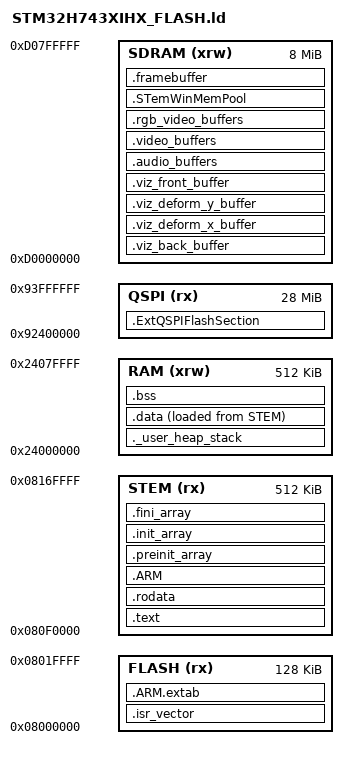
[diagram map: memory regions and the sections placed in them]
/*
******************************************************************************
**
** @file        : LinkerScript.ld
**
** @author      : Auto-generated by STM32CubeIDE
**
**  Abstract    : Linker script for STM32H743I-EVAL Board embedding STM32H743XIHx Device from stm32h7 series
**                      28672Kbytes QSPI
**                      512Kbytes ROM
**                      512Kbytes RAM
**                      32768Kbytes SDRAM
**
**                Set heap size, stack size and stack location according
**                to application requirements.
**
**                Set memory bank area and size if external memory is used
**
**  Target      : STMicroelectronics STM32
**
**  Distribution: The file is distributed as is, without any warranty
**                of any kind.
**
******************************************************************************
** @attention
**
** Copyright (c) 2022 STMicroelectronics.
** All rights reserved.
**
** This software is licensed under terms that can be found in the LICENSE file
** in the root directory of this software component.
** If no LICENSE file comes with this software, it is provided AS-IS.
**
******************************************************************************
*/

/* Entry Point */
ENTRY(Reset_Handler)

/* Highest address of the user mode stack */
_estack = 0x24080000;    /* end of RAM */
/* Generate a link error if heap   and stack don't fit into RAM */
_Min_Heap_Size = 0x7000;      /* required amount of heap  */
_Min_Stack_Size = 0x3000; /* required amount of stack */

/* Specify the memory areas */
MEMORY
{
FLASH (rx)      : ORIGIN = 0x08000000, LENGTH = 128K
RAM (xrw)      : ORIGIN = 0x24000000, LENGTH = 512K
STEM (rx)      : ORIGIN = 0x080F0000, LENGTH = 512K 
SDRAM    (xrw)    : ORIGIN = 0xD0000000,   LENGTH = 8192K
QSPI    (rx)    : ORIGIN = 0x92400000,   LENGTH = 28672K
}

/* Define output sections */
SECTIONS
{
  /* The startup code goes first into FLASH */
  .isr_vector :
  {
    . = ALIGN(4);
    KEEP(*(.isr_vector)) /* Startup code */
    . = ALIGN(4);
  } >FLASH

  /* The program code and other data goes into FLASH */
  .text :
  {
    . = ALIGN(4);
    *(.text)           /* .text sections (code) */
    *(.text*)          /* .text* sections (code) */
    *(.glue_7)         /* glue arm to thumb code */
    *(.glue_7t)        /* glue thumb to arm code */
    *(.eh_frame)

    KEEP (*(.init))
    KEEP (*(.fini))

    . = ALIGN(4);
    _etext = .;        /* define a global symbols at end of code */
  } >STEM

  /* Constant data goes into FLASH */
  .rodata :
  {
    . = ALIGN(4);
    *(.rodata)         /* .rodata sections (constants, strings, etc.) */
    *(.rodata*)        /* .rodata* sections (constants, strings, etc.) */
    . = ALIGN(4);
  } >STEM

  .ARM.extab   : { *(.ARM.extab* .gnu.linkonce.armextab.*) } >FLASH
  .ARM : {
    __exidx_start = .;
    *(.ARM.exidx*)
    __exidx_end = .;
  } >STEM

  .preinit_array     :
  {
    PROVIDE_HIDDEN (__preinit_array_start = .);
    KEEP (*(.preinit_array*))
    PROVIDE_HIDDEN (__preinit_array_end = .);
  } >STEM
  .init_array :
  {
    PROVIDE_HIDDEN (__init_array_start = .);
    KEEP (*(SORT(.init_array.*)))
    KEEP (*(.init_array*))
    PROVIDE_HIDDEN (__init_array_end = .);
  } >STEM
  .fini_array :
  {
    PROVIDE_HIDDEN (__fini_array_start = .);
    KEEP (*(SORT(.fini_array.*)))
    KEEP (*(.fini_array*))
    PROVIDE_HIDDEN (__fini_array_end = .);
  } >STEM

  /* used by the startup to initialize data */
  _sidata = LOADADDR(.data);
 /* User_heap_stack section, used to check that there is enough RAM left */
  ._user_heap_stack :
  {
    . = ALIGN(8);
    PROVIDE ( end = . );
    PROVIDE ( _end = . );
    . = . + _Min_Heap_Size;
    . = . + _Min_Stack_Size;
    . = ALIGN(8);
  } >RAM
  
  

	
  /* Initialized data sections goes into RAM, load LMA copy after code */
  .data : 
  {
    . = ALIGN(4);
    _sdata = .;        /* create a global symbol at data start */
    *(.data)           /* .data sections */
    *(.data*)          /* .data* sections */

    . = ALIGN(4);
    _edata = .;        /* define a global symbol at data end */
  } >RAM AT> STEM

   
  /* Uninitialized data section */
  . = ALIGN(4);
  .bss :
  {
    /* This is used by the startup in order to initialize the .bss section */
    _sbss = .;         /* define a global symbol at bss start */
    __bss_start__ = _sbss;
    *(.bss)
    *(.bss*)
    *(COMMON)

    . = ALIGN(4);
    _ebss = .;         /* define a global symbol at bss end */
    __bss_end__ = _ebss;
  } >RAM

 

  

  /* Remove information from the standard libraries */
  /DISCARD/ :
  {
    libc.a ( * )
    libm.a ( * )
    libgcc.a ( * )
  }

  .ARM.attributes 0 : { *(.ARM.attributes) }
  .ExtQSPIFlashSection : { *(.ExtQSPIFlashSection) } >QSPI
  .viz_back_buffer (NOLOAD): { *(.viz_back_buffer) } > SDRAM
  .viz_deform_x_buffer(NOLOAD): { *(.viz_deform_x_buffer) } > SDRAM
  .viz_deform_y_buffer(NOLOAD): { *(.viz_deform_y_buffer) } > SDRAM
  .viz_front_buffer(NOLOAD): { *(.viz_front_buffer) } > SDRAM
  .audio_buffers (NOLOAD): { *(.audio_buffers) } > SDRAM
  .video_buffers (NOLOAD) : { *(.video_buffers) } > SDRAM
  .rgb_video_buffers (NOLOAD): { *(.rgb_video_buffers) } > SDRAM
  .STemWinMemPool (NOLOAD): { *(.STemWinMemPool) } > SDRAM
  .framebuffer   (NOLOAD) : { *(.framebuffer) } > SDRAM
}
